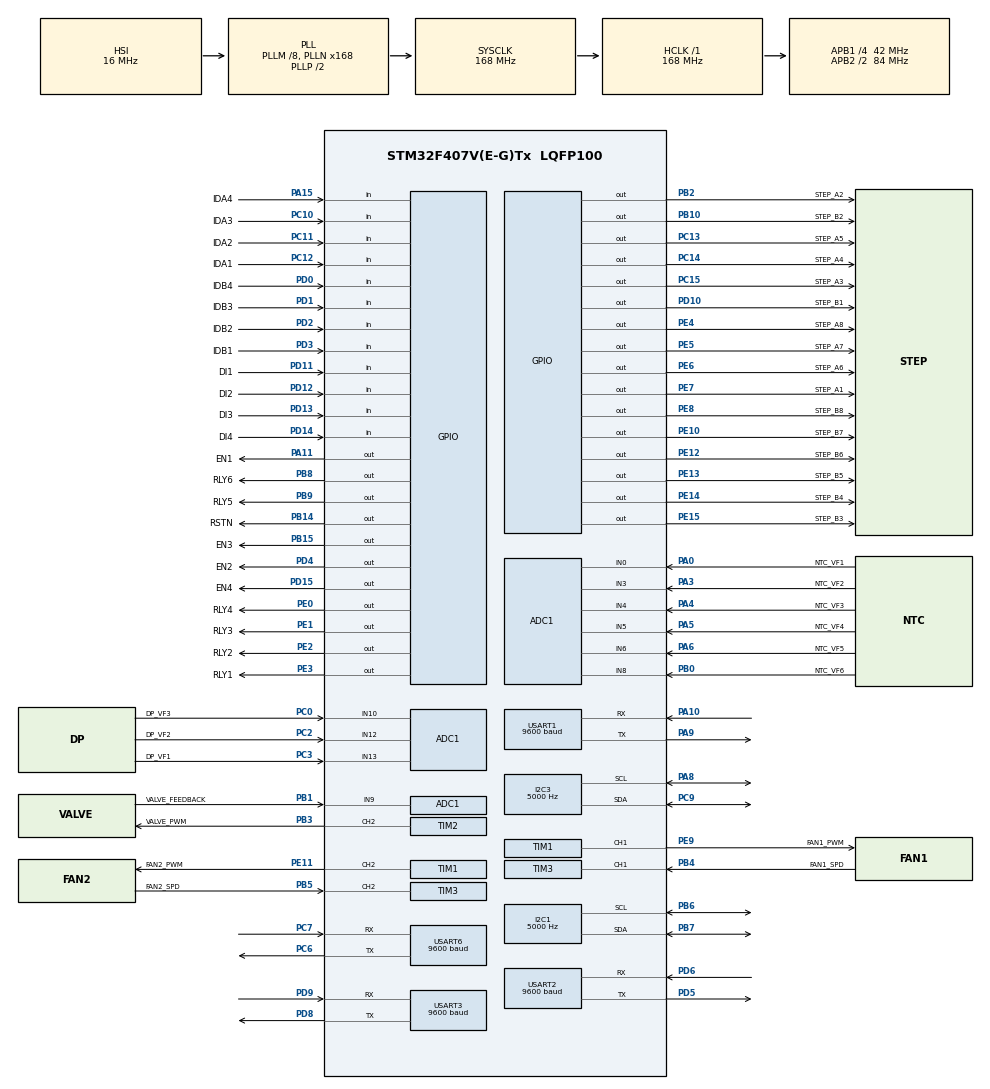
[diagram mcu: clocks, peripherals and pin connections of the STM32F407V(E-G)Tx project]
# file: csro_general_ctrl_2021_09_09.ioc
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ADC1.Channel-0\#ChannelRegularConversion=ADC_CHANNEL_13
ADC1.Channel-1\#ChannelRegularConversion=ADC_CHANNEL_12
ADC1.Channel-10\#ChannelRegularConversion=ADC_CHANNEL_TEMPSENSOR
ADC1.Channel-11\#ChannelRegularConversion=ADC_CHANNEL_VREFINT
ADC1.Channel-12\#ChannelRegularConversion=ADC_CHANNEL_VBAT
ADC1.Channel-2\#ChannelRegularConversion=ADC_CHANNEL_10
ADC1.Channel-3\#ChannelRegularConversion=ADC_CHANNEL_9
ADC1.Channel-4\#ChannelRegularConversion=ADC_CHANNEL_0
ADC1.Channel-5\#ChannelRegularConversion=ADC_CHANNEL_3
ADC1.Channel-6\#ChannelRegularConversion=ADC_CHANNEL_4
ADC1.Channel-7\#ChannelRegularConversion=ADC_CHANNEL_5
ADC1.Channel-8\#ChannelRegularConversion=ADC_CHANNEL_6
ADC1.Channel-9\#ChannelRegularConversion=ADC_CHANNEL_8
ADC1.ContinuousConvMode=ENABLE
ADC1.DMAContinuousRequests=ENABLE
ADC1.NbrOfConversion=13
ADC1.NbrOfConversionFlag=1
ADC1.Rank-0\#ChannelRegularConversion=1
ADC1.Rank-1\#ChannelRegularConversion=2
ADC1.Rank-10\#ChannelRegularConversion=11
ADC1.Rank-11\#ChannelRegularConversion=12
ADC1.Rank-12\#ChannelRegularConversion=13
ADC1.Rank-2\#ChannelRegularConversion=3
ADC1.Rank-3\#ChannelRegularConversion=4
ADC1.Rank-4\#ChannelRegularConversion=5
ADC1.Rank-5\#ChannelRegularConversion=6
ADC1.Rank-6\#ChannelRegularConversion=7
ADC1.Rank-7\#ChannelRegularConversion=8
ADC1.Rank-8\#ChannelRegularConversion=9
ADC1.Rank-9\#ChannelRegularConversion=10
ADC1.SamplingTime-0\#ChannelRegularConversion=ADC_SAMPLETIME_144CYCLES
ADC1.SamplingTime-1\#ChannelRegularConversion=ADC_SAMPLETIME_144CYCLES
ADC1.SamplingTime-10\#ChannelRegularConversion=ADC_SAMPLETIME_144CYCLES
ADC1.SamplingTime-11\#ChannelRegularConversion=ADC_SAMPLETIME_144CYCLES
ADC1.SamplingTime-12\#ChannelRegularConversion=ADC_SAMPLETIME_144CYCLES
ADC1.SamplingTime-2\#ChannelRegularConversion=ADC_SAMPLETIME_144CYCLES
ADC1.SamplingTime-3\#ChannelRegularConversion=ADC_SAMPLETIME_144CYCLES
ADC1.SamplingTime-4\#ChannelRegularConversion=ADC_SAMPLETIME_144CYCLES
ADC1.SamplingTime-5\#ChannelRegularConversion=ADC_SAMPLETIME_144CYCLES
ADC1.SamplingTime-6\#ChannelRegularConversion=ADC_SAMPLETIME_144CYCLES
ADC1.SamplingTime-7\#ChannelRegularConversion=ADC_SAMPLETIME_144CYCLES
ADC1.SamplingTime-8\#ChannelRegularConversion=ADC_SAMPLETIME_144CYCLES
ADC1.SamplingTime-9\#ChannelRegularConversion=ADC_SAMPLETIME_144CYCLES
ADC1.ScanConvMode=ENABLE
ADC1.master=1
Dma.ADC1.0.Direction=DMA_PERIPH_TO_MEMORY
Dma.ADC1.0.FIFOMode=DMA_FIFOMODE_DISABLE
Dma.ADC1.0.Instance=DMA2_Stream0
Dma.ADC1.0.MemDataAlignment=DMA_MDATAALIGN_WORD
Dma.ADC1.0.MemInc=DMA_MINC_ENABLE
Dma.ADC1.0.Mode=DMA_CIRCULAR
Dma.ADC1.0.PeriphDataAlignment=DMA_PDATAALIGN_WORD
Dma.ADC1.0.PeriphInc=DMA_PINC_DISABLE
Dma.ADC1.0.Priority=DMA_PRIORITY_LOW
Dma.Request0=ADC1
Dma.Request1=USART1_RX
Dma.Request2=USART1_TX
Dma.Request3=USART2_RX
Dma.Request4=USART2_TX
Dma.Request5=USART3_RX
Dma.Request6=USART3_TX
Dma.Request7=USART6_RX
Dma.Request8=USART6_TX
Dma.USART1_RX.1.Direction=DMA_PERIPH_TO_MEMORY
Dma.USART1_RX.1.FIFOMode=DMA_FIFOMODE_DISABLE
Dma.USART1_RX.1.Instance=DMA2_Stream2
Dma.USART1_RX.1.MemDataAlignment=DMA_MDATAALIGN_BYTE
Dma.USART1_RX.1.MemInc=DMA_MINC_ENABLE
Dma.USART1_RX.1.Mode=DMA_CIRCULAR
Dma.USART1_RX.1.PeriphDataAlignment=DMA_PDATAALIGN_BYTE
Dma.USART1_RX.1.PeriphInc=DMA_PINC_DISABLE
Dma.USART1_RX.1.Priority=DMA_PRIORITY_LOW
Dma.USART1_TX.2.Direction=DMA_MEMORY_TO_PERIPH
Dma.USART1_TX.2.FIFOMode=DMA_FIFOMODE_DISABLE
Dma.USART1_TX.2.Instance=DMA2_Stream7
Dma.USART1_TX.2.MemDataAlignment=DMA_MDATAALIGN_BYTE
Dma.USART1_TX.2.MemInc=DMA_MINC_ENABLE
Dma.USART1_TX.2.Mode=DMA_NORMAL
Dma.USART1_TX.2.PeriphDataAlignment=DMA_PDATAALIGN_BYTE
Dma.USART1_TX.2.PeriphInc=DMA_PINC_DISABLE
Dma.USART1_TX.2.Priority=DMA_PRIORITY_LOW
Dma.USART2_RX.3.Direction=DMA_PERIPH_TO_MEMORY
Dma.USART2_RX.3.FIFOMode=DMA_FIFOMODE_DISABLE
Dma.USART2_RX.3.Instance=DMA1_Stream5
Dma.USART2_RX.3.MemDataAlignment=DMA_MDATAALIGN_BYTE
Dma.USART2_RX.3.MemInc=DMA_MINC_ENABLE
Dma.USART2_RX.3.Mode=DMA_CIRCULAR
Dma.USART2_RX.3.PeriphDataAlignment=DMA_PDATAALIGN_BYTE
Dma.USART2_RX.3.PeriphInc=DMA_PINC_DISABLE
Dma.USART2_RX.3.Priority=DMA_PRIORITY_LOW
Dma.USART2_TX.4.Direction=DMA_MEMORY_TO_PERIPH
Dma.USART2_TX.4.FIFOMode=DMA_FIFOMODE_DISABLE
Dma.USART2_TX.4.Instance=DMA1_Stream6
Dma.USART2_TX.4.MemDataAlignment=DMA_MDATAALIGN_BYTE
Dma.USART2_TX.4.MemInc=DMA_MINC_ENABLE
Dma.USART2_TX.4.Mode=DMA_NORMAL
Dma.USART2_TX.4.PeriphDataAlignment=DMA_PDATAALIGN_BYTE
Dma.USART2_TX.4.PeriphInc=DMA_PINC_DISABLE
Dma.USART2_TX.4.Priority=DMA_PRIORITY_LOW
Dma.USART3_RX.5.Direction=DMA_PERIPH_TO_MEMORY
Dma.USART3_RX.5.FIFOMode=DMA_FIFOMODE_DISABLE
Dma.USART3_RX.5.Instance=DMA1_Stream1
Dma.USART3_RX.5.MemDataAlignment=DMA_MDATAALIGN_BYTE
Dma.USART3_RX.5.MemInc=DMA_MINC_ENABLE
Dma.USART3_RX.5.Mode=DMA_CIRCULAR
Dma.USART3_RX.5.PeriphDataAlignment=DMA_PDATAALIGN_BYTE
Dma.USART3_RX.5.PeriphInc=DMA_PINC_DISABLE
Dma.USART3_RX.5.Priority=DMA_PRIORITY_LOW
Dma.USART3_TX.6.Direction=DMA_MEMORY_TO_PERIPH
Dma.USART3_TX.6.FIFOMode=DMA_FIFOMODE_DISABLE
Dma.USART3_TX.6.Instance=DMA1_Stream3
Dma.USART3_TX.6.MemDataAlignment=DMA_MDATAALIGN_BYTE
Dma.USART3_TX.6.MemInc=DMA_MINC_ENABLE
Dma.USART3_TX.6.Mode=DMA_NORMAL
Dma.USART3_TX.6.PeriphDataAlignment=DMA_PDATAALIGN_BYTE
Dma.USART3_TX.6.PeriphInc=DMA_PINC_DISABLE
Dma.USART3_TX.6.Priority=DMA_PRIORITY_LOW
Dma.USART6_RX.7.Direction=DMA_PERIPH_TO_MEMORY
Dma.USART6_RX.7.FIFOMode=DMA_FIFOMODE_DISABLE
Dma.USART6_RX.7.Instance=DMA2_Stream1
Dma.USART6_RX.7.MemDataAlignment=DMA_MDATAALIGN_BYTE
Dma.USART6_RX.7.MemInc=DMA_MINC_ENABLE
Dma.USART6_RX.7.Mode=DMA_CIRCULAR
Dma.USART6_RX.7.PeriphDataAlignment=DMA_PDATAALIGN_BYTE
Dma.USART6_RX.7.PeriphInc=DMA_PINC_DISABLE
Dma.USART6_RX.7.Priority=DMA_PRIORITY_LOW
Dma.USART6_TX.8.Direction=DMA_MEMORY_TO_PERIPH
Dma.USART6_TX.8.FIFOMode=DMA_FIFOMODE_DISABLE
Dma.USART6_TX.8.Instance=DMA2_Stream6
Dma.USART6_TX.8.MemDataAlignment=DMA_MDATAALIGN_BYTE
Dma.USART6_TX.8.MemInc=DMA_MINC_ENABLE
Dma.USART6_TX.8.Mode=DMA_NORMAL
Dma.USART6_TX.8.PeriphDataAlignment=DMA_PDATAALIGN_BYTE
Dma.USART6_TX.8.PeriphInc=DMA_PINC_DISABLE
Dma.USART6_TX.8.Priority=DMA_PRIORITY_LOW
FREERTOS.Queues01=Queue01,16,uint16_t,0,Dynamic,NULL,NULL;Queue02,16,uint16_t,0,Dynamic,NULL,NULL
FREERTOS.Tasks01=Task01,55,128,StartTask01,Default,NULL,Dynamic,NULL,NULL;Task02,53,128,StartTask02,Default,NULL,Dynamic,NULL,NULL;Task03,51,128,StartTask03,Default,NULL,Dynamic,NULL,NULL;Task04,49,128,StartTask04,Default,NULL,Dynamic,NULL,NULL;Task05,47,128,StartTask05,Default,NULL,Dynamic,NULL,NULL;Task06,45,128,StartTask06,Default,NULL,Dynamic,NULL,NULL;Task07,43,128,StartTask07,Default,NULL,Dynamic,NULL,NULL;Task08,41,128,StartTask08,Default,NULL,Dynamic,NULL,NULL
FREERTOS.configUSE_NEWLIB_REENTRANT=1
I2C1.ClockSpeed=5000
I2C3.ClockSpeed=5000
Mcu.Family=STM32F4
Mcu.Name=STM32F407V(E-G)Tx
Mcu.Package=LQFP100
NVIC.ADC_IRQn=true\:5\:0\:false\:false\:true\:true\:true\:true
NVIC.DMA1_Stream1_IRQn=true\:5\:0\:false\:false\:true\:true\:false\:true
NVIC.DMA1_Stream3_IRQn=true\:5\:0\:false\:false\:true\:true\:false\:true
NVIC.DMA1_Stream5_IRQn=true\:5\:0\:false\:false\:true\:true\:false\:true
NVIC.DMA1_Stream6_IRQn=true\:5\:0\:false\:false\:true\:true\:false\:true
NVIC.DMA2_Stream0_IRQn=true\:5\:0\:false\:false\:true\:false\:false\:true
NVIC.DMA2_Stream1_IRQn=true\:5\:0\:false\:false\:true\:true\:false\:true
NVIC.DMA2_Stream2_IRQn=true\:5\:0\:false\:false\:true\:true\:false\:true
NVIC.DMA2_Stream6_IRQn=true\:5\:0\:false\:false\:true\:true\:false\:true
NVIC.DMA2_Stream7_IRQn=true\:5\:0\:false\:false\:true\:true\:false\:true
NVIC.PriorityGroup=NVIC_PRIORITYGROUP_4
NVIC.TIM3_IRQn=true\:5\:0\:false\:false\:true\:true\:true\:true
NVIC.TIM8_TRG_COM_TIM14_IRQn=true\:15\:0\:false\:false\:true\:false\:false\:true
NVIC.TimeBase=TIM8_TRG_COM_TIM14_IRQn
NVIC.TimeBaseIP=TIM14
NVIC.USART1_IRQn=true\:5\:0\:false\:false\:true\:true\:true\:true
NVIC.USART2_IRQn=true\:5\:0\:false\:false\:true\:true\:true\:true
NVIC.USART3_IRQn=true\:5\:0\:false\:false\:true\:true\:true\:true
NVIC.USART6_IRQn=true\:5\:0\:false\:false\:true\:true\:true\:true
PA0-WKUP.GPIO_Label=NTC_VF1
PA0-WKUP.Signal=ADCx_IN0
PA10.Mode=Asynchronous
PA10.Signal=USART1_RX
PA11.GPIO_Label=EN1
PA11.Signal=GPIO_Output
PA13.Mode=Serial_Wire
PA13.Signal=SYS_JTMS-SWDIO
PA14.Mode=Serial_Wire
PA14.Signal=SYS_JTCK-SWCLK
PA15.GPIO_Label=IDA4
PA15.Signal=GPIO_Input
PA3.GPIO_Label=NTC_VF2
PA3.Signal=ADCx_IN3
PA4.GPIO_Label=NTC_VF3
PA4.Signal=ADCx_IN4
PA5.GPIO_Label=NTC_VF4
PA5.Signal=ADCx_IN5
PA6.GPIO_Label=NTC_VF5
PA6.Signal=ADCx_IN6
PA8.Mode=I2C
PA8.Signal=I2C3_SCL
PA9.Mode=Asynchronous
PA9.Signal=USART1_TX
PB0.GPIO_Label=NTC_VF6
PB0.Signal=ADCx_IN8
PB1.GPIO_Label=VALVE_FEEDBACK
PB1.Signal=ADCx_IN9
PB10.GPIO_Label=STEP_B2
PB10.Signal=GPIO_Output
PB14.GPIO_Label=RSTN
PB14.Signal=GPIO_Output
PB15.GPIO_Label=EN3
PB15.Signal=GPIO_Output
PB2.GPIO_Label=STEP_A2
PB2.Signal=GPIO_Output
PB3.GPIO_Label=VALVE_PWM
PB3.Signal=S_TIM2_CH2
PB4.GPIO_Label=FAN1_SPD
PB4.Signal=S_TIM3_CH1
PB5.GPIO_Label=FAN2_SPD
PB5.Signal=S_TIM3_CH2
PB6.Mode=I2C
PB6.Signal=I2C1_SCL
PB7.Mode=I2C
PB7.Signal=I2C1_SDA
PB8.GPIO_Label=RLY6
PB8.Signal=GPIO_Output
PB9.GPIO_Label=RLY5
PB9.Signal=GPIO_Output
PC0.GPIO_Label=DP_VF3
PC0.Signal=ADCx_IN10
PC10.GPIO_Label=IDA3
PC10.Signal=GPIO_Input
PC11.GPIO_Label=IDA2
PC11.Signal=GPIO_Input
PC12.GPIO_Label=IDA1
PC12.Signal=GPIO_Input
PC13-ANTI_TAMP.GPIO_Label=STEP_A5
PC13-ANTI_TAMP.Signal=GPIO_Output
PC14-OSC32_IN.GPIO_Label=STEP_A4
PC14-OSC32_IN.Signal=GPIO_Output
PC15-OSC32_OUT.GPIO_Label=STEP_A3
PC15-OSC32_OUT.Signal=GPIO_Output
PC2.GPIO_Label=DP_VF2
PC2.Signal=ADCx_IN12
PC3.GPIO_Label=DP_VF1
PC3.Signal=ADCx_IN13
PC6.Mode=Asynchronous
PC6.Signal=USART6_TX
PC7.Mode=Asynchronous
PC7.Signal=USART6_RX
PC9.Mode=I2C
PC9.Signal=I2C3_SDA
PD0.GPIO_Label=IDB4
PD0.Signal=GPIO_Input
PD1.GPIO_Label=IDB3
PD1.Signal=GPIO_Input
PD10.GPIO_Label=STEP_B1
PD10.Signal=GPIO_Output
PD11.GPIO_Label=DI1
PD11.Signal=GPIO_Input
PD12.GPIO_Label=DI2
PD12.Signal=GPIO_Input
PD13.GPIO_Label=DI3
PD13.Signal=GPIO_Input
PD14.GPIO_Label=DI4
PD14.Signal=GPIO_Input
PD15.GPIO_Label=EN4
PD15.Signal=GPIO_Output
PD2.GPIO_Label=IDB2
PD2.Signal=GPIO_Input
PD3.GPIO_Label=IDB1
PD3.Signal=GPIO_Input
PD4.GPIO_Label=EN2
PD4.Signal=GPIO_Output
PD5.Mode=Asynchronous
PD5.Signal=USART2_TX
PD6.Mode=Asynchronous
PD6.Signal=USART2_RX
PD8.Mode=Asynchronous
PD8.Signal=USART3_TX
PD9.Mode=Asynchronous
PD9.Signal=USART3_RX
PE0.GPIO_Label=RLY4
PE0.Signal=GPIO_Output
PE1.GPIO_Label=RLY3
PE1.Signal=GPIO_Output
PE10.GPIO_Label=STEP_B7
PE10.Signal=GPIO_Output
PE11.GPIO_Label=FAN2_PWM
PE11.Signal=S_TIM1_CH2
PE12.GPIO_Label=STEP_B6
PE12.Signal=GPIO_Output
PE13.GPIO_Label=STEP_B5
PE13.Signal=GPIO_Output
PE14.GPIO_Label=STEP_B4
PE14.Signal=GPIO_Output
PE15.GPIO_Label=STEP_B3
PE15.Signal=GPIO_Output
PE2.GPIO_Label=RLY2
PE2.Signal=GPIO_Output
PE3.GPIO_Label=RLY1
PE3.Signal=GPIO_Output
PE4.GPIO_Label=STEP_A8
PE4.Signal=GPIO_Output
PE5.GPIO_Label=STEP_A7
PE5.Signal=GPIO_Output
PE6.GPIO_Label=STEP_A6
PE6.Signal=GPIO_Output
PE7.GPIO_Label=STEP_A1
PE7.Signal=GPIO_Output
PE8.GPIO_Label=STEP_B8
PE8.Signal=GPIO_Output
PE9.GPIO_Label=FAN1_PWM
PE9.Signal=S_TIM1_CH1
ProjectManager.HeapSize=0x800
ProjectManager.StackSize=0x800
ProjectManager.TargetToolchain=STM32CubeIDE
RCC.48MHZClocksFreq_Value=84000000
RCC.AHBFreq_Value=168000000
RCC.APB1CLKDivider=RCC_HCLK_DIV4
RCC.APB1Freq_Value=42000000
RCC.APB1TimFreq_Value=84000000
RCC.APB2CLKDivider=RCC_HCLK_DIV2
RCC.APB2Freq_Value=84000000
RCC.APB2TimFreq_Value=168000000
RCC.CortexFreq_Value=168000000
RCC.HCLKFreq_Value=168000000
RCC.HSE_VALUE=25000000
RCC.HSI_VALUE=16000000
RCC.LSE_VALUE=32768
RCC.PLLM=8
RCC.PLLN=168
RCC.SYSCLKFreq_VALUE=168000000
RCC.SYSCLKSource=RCC_SYSCLKSOURCE_PLLCLK
RCC.VCOOutputFreq_Value=336000000
SH.ADCx_IN0.0=ADC1_IN0,IN0
SH.ADCx_IN10.0=ADC1_IN10,IN10
SH.ADCx_IN12.0=ADC1_IN12,IN12
SH.ADCx_IN13.0=ADC1_IN13,IN13
SH.ADCx_IN3.0=ADC1_IN3,IN3
SH.ADCx_IN4.0=ADC1_IN4,IN4
SH.ADCx_IN5.0=ADC1_IN5,IN5
SH.ADCx_IN6.0=ADC1_IN6,IN6
SH.ADCx_IN8.0=ADC1_IN8,IN8
SH.ADCx_IN9.0=ADC1_IN9,IN9
SH.S_TIM1_CH1.0=TIM1_CH1,PWM Generation1 CH1
SH.S_TIM1_CH2.0=TIM1_CH2,PWM Generation2 CH2
SH.S_TIM2_CH2.0=TIM2_CH2,PWM Generation2 CH2
SH.S_TIM3_CH1.0=TIM3_CH1,Input_Capture1_from_TI1
SH.S_TIM3_CH2.0=TIM3_CH2,Input_Capture2_from_TI2
TIM1.Channel-PWM\ Generation1\ CH1=TIM_CHANNEL_1
TIM1.Channel-PWM\ Generation2\ CH2=TIM_CHANNEL_2
TIM1.Period=1000
TIM1.Prescaler=167
TIM1.Pulse-PWM\ Generation1\ CH1=300
TIM1.Pulse-PWM\ Generation2\ CH2=600
TIM2.Channel-PWM\ Generation2\ CH2=TIM_CHANNEL_2
TIM2.Period=1000
TIM2.Prescaler=167
TIM2.Pulse-PWM\ Generation2\ CH2=500
TIM3.Channel-Input_Capture1_from_TI1=TIM_CHANNEL_1
TIM3.Channel-Input_Capture2_from_TI2=TIM_CHANNEL_2
USART1.BaudRate=9600
USART1.VirtualMode=VM_ASYNC
USART2.BaudRate=9600
USART2.VirtualMode=VM_ASYNC
USART3.BaudRate=9600
USART3.VirtualMode=VM_ASYNC
USART6.BaudRate=9600
USART6.VirtualMode=VM_ASYNC
VP_ADC1_TempSens_Input.Mode=IN-TempSens
VP_ADC1_Vbat_Input.Mode=IN-Vbat
VP_ADC1_Vref_Input.Mode=IN-Vrefint
VP_FREERTOS_VS_CMSIS_V2.Mode=CMSIS_V2
VP_SYS_VS_tim14.Mode=TIM14
VP_TIM1_VS_ClockSourceINT.Mode=Internal
VP_TIM2_VS_ClockSourceINT.Mode=Internal
VP_TIM3_VS_ClockSourceINT.Mode=Internal
board=custom

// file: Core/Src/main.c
/* USER CODE BEGIN Header */
/**
  ******************************************************************************
  * @file           : main.c
  * @brief          : Main program body
  ******************************************************************************
  * @attention
  *
  * <h2><center>&copy; Copyright (c) 2021 STMicroelectronics.
  * All rights reserved.</center></h2>
  *
  * This software component is licensed by ST under BSD 3-Clause license,
  * the "License"; You may not use this file except in compliance with the
  * License. You may obtain a copy of the License at:
  *                        opensource.org/licenses/BSD-3-Clause
  *
  ******************************************************************************
  */
/* USER CODE END Header */
#include "main.h"
#include "cmsis_os.h"
#include "adc.h"
#include "dma.h"
#include "i2c.h"
#include "tim.h"
#include "usart.h"
#include "gpio.h"

void SystemClock_Config(void);
void MX_FREERTOS_Init(void);

int main(void)
{

  /* MCU Configuration--------------------------------------------------------*/

  /* Reset of all peripherals, Initializes the Flash interface and the Systick. */
  HAL_Init();

  /* Configure the system clock */
  SystemClock_Config();

  /* Initialize all configured peripherals */
  MX_GPIO_Init();
  MX_DMA_Init();
  MX_ADC1_Init();
  MX_I2C1_Init();
  MX_I2C3_Init();
  MX_TIM1_Init();
  MX_TIM2_Init();
  MX_TIM3_Init();
  MX_USART1_UART_Init();
  MX_USART2_UART_Init();
  MX_USART3_UART_Init();
  MX_USART6_UART_Init();

  /* Init scheduler */
  osKernelInitialize();  /* Call init function for freertos objects (in freertos.c) */
  MX_FREERTOS_Init();
  /* Start scheduler */
  osKernelStart();

  /* We should never get here as control is now taken by the scheduler */
  /* Infinite loop */
  while (1)
  {

  }
}

void SystemClock_Config(void)
{
  RCC_OscInitTypeDef RCC_OscInitStruct = {0};
  RCC_ClkInitTypeDef RCC_ClkInitStruct = {0};

  /** Configure the main internal regulator output voltage
  */
  __HAL_RCC_PWR_CLK_ENABLE();
  __HAL_PWR_VOLTAGESCALING_CONFIG(PWR_REGULATOR_VOLTAGE_SCALE1);
  /** Initializes the RCC Oscillators according to the specified parameters
  * in the RCC_OscInitTypeDef structure.
  */
  RCC_OscInitStruct.OscillatorType = RCC_OSCILLATORTYPE_HSI;
  RCC_OscInitStruct.HSIState = RCC_HSI_ON;
  RCC_OscInitStruct.HSICalibrationValue = RCC_HSICALIBRATION_DEFAULT;
  RCC_OscInitStruct.PLL.PLLState = RCC_PLL_ON;
  RCC_OscInitStruct.PLL.PLLSource = RCC_PLLSOURCE_HSI;
  RCC_OscInitStruct.PLL.PLLM = 8;
  RCC_OscInitStruct.PLL.PLLN = 168;
  RCC_OscInitStruct.PLL.PLLP = RCC_PLLP_DIV2;
  RCC_OscInitStruct.PLL.PLLQ = 4;
  if (HAL_RCC_OscConfig(&RCC_OscInitStruct) != HAL_OK)
  {
    Error_Handler();
  }
  /** Initializes the CPU, AHB and APB buses clocks
  */
  RCC_ClkInitStruct.ClockType = RCC_CLOCKTYPE_HCLK|RCC_CLOCKTYPE_SYSCLK
                              |RCC_CLOCKTYPE_PCLK1|RCC_CLOCKTYPE_PCLK2;
  RCC_ClkInitStruct.SYSCLKSource = RCC_SYSCLKSOURCE_PLLCLK;
  RCC_ClkInitStruct.AHBCLKDivider = RCC_SYSCLK_DIV1;
  RCC_ClkInitStruct.APB1CLKDivider = RCC_HCLK_DIV4;
  RCC_ClkInitStruct.APB2CLKDivider = RCC_HCLK_DIV2;

  if (HAL_RCC_ClockConfig(&RCC_ClkInitStruct, FLASH_LATENCY_5) != HAL_OK)
  {
    Error_Handler();
  }
}

void HAL_TIM_PeriodElapsedCallback(TIM_HandleTypeDef *htim)
{
  if (htim->Instance == TIM14) {
    HAL_IncTick();
  }
}

void Error_Handler(void)
{
  __disable_irq();
  while (1)
  {
  }
}

/************************ (C) COPYRIGHT STMicroelectronics *****END OF FILE****/

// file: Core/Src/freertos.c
/* USER CODE BEGIN Header */
/**
  ******************************************************************************
  * File Name          : freertos.c
  * Description        : Code for freertos applications
  ******************************************************************************
  * @attention
  *
  * <h2><center>&copy; Copyright (c) 2021 STMicroelectronics.
  * All rights reserved.</center></h2>
  *
  * This software component is licensed by ST under Ultimate Liberty license
  * SLA0044, the "License"; You may not use this file except in compliance with
  * the License. You may obtain a copy of the License at:
  *                             www.st.com/SLA0044
  *
  ******************************************************************************
  */
/* USER CODE END Header */

#include "FreeRTOS.h"
#include "task.h"
#include "main.h"
#include "cmsis_os.h"

/* USER CODE BEGIN Includes */
#include "fnd_input.h"
#include "fnd_output.h"
#include "fnd_com.h"

/* USER CODE END Includes */

/* Definitions for Task01 */
osThreadId_t Task01Handle;
const osThreadAttr_t Task01_attributes = {
    .name = "Task01",
    .stack_size = 128 * 4,
    .priority = (osPriority_t)osPriorityRealtime7,
};
/* Definitions for Task02 */
osThreadId_t Task02Handle;
const osThreadAttr_t Task02_attributes = {
    .name = "Task02",
    .stack_size = 128 * 4,
    .priority = (osPriority_t)osPriorityRealtime5,
};
/* Definitions for Task03 */
osThreadId_t Task03Handle;
const osThreadAttr_t Task03_attributes = {
    .name = "Task03",
    .stack_size = 128 * 4,
    .priority = (osPriority_t)osPriorityRealtime3,
};
/* Definitions for Task04 */
osThreadId_t Task04Handle;
const osThreadAttr_t Task04_attributes = {
    .name = "Task04",
    .stack_size = 128 * 4,
    .priority = (osPriority_t)osPriorityRealtime1,
};
/* Definitions for Task05 */
osThreadId_t Task05Handle;
const osThreadAttr_t Task05_attributes = {
    .name = "Task05",
    .stack_size = 128 * 4,
    .priority = (osPriority_t)osPriorityHigh7,
};
/* Definitions for Task06 */
osThreadId_t Task06Handle;
const osThreadAttr_t Task06_attributes = {
    .name = "Task06",
    .stack_size = 128 * 4,
    .priority = (osPriority_t)osPriorityHigh5,
};
/* Definitions for Task07 */
osThreadId_t Task07Handle;
const osThreadAttr_t Task07_attributes = {
    .name = "Task07",
    .stack_size = 128 * 4,
    .priority = (osPriority_t)osPriorityHigh3,
};
/* Definitions for Task08 */
osThreadId_t Task08Handle;
const osThreadAttr_t Task08_attributes = {
    .name = "Task08",
    .stack_size = 128 * 4,
    .priority = (osPriority_t)osPriorityHigh1,
};
/* Definitions for Queue01 */
osMessageQueueId_t Queue01Handle;
const osMessageQueueAttr_t Queue01_attributes = {
    .name = "Queue01"};
/* Definitions for Queue02 */
osMessageQueueId_t Queue02Handle;
const osMessageQueueAttr_t Queue02_attributes = {
    .name = "Queue02"};

void StartTask01(void *argument);
void StartTask02(void *argument);
void StartTask03(void *argument);
void StartTask04(void *argument);
void StartTask05(void *argument);
void StartTask06(void *argument);
void StartTask07(void *argument);
void StartTask08(void *argument);

void MX_FREERTOS_Init(void); /* (MISRA C 2004 rule 8.1) */

void MX_FREERTOS_Init(void)
{
  /* USER CODE BEGIN Init */
  fnd_com_modbus_rtu_init();

  /* USER CODE END Init */

  /* Create the queue(s) */
  /* creation of Queue01 */
  Queue01Handle = osMessageQueueNew(16, sizeof(uint16_t), &Queue01_attributes);

  /* creation of Queue02 */
  Queue02Handle = osMessageQueueNew(16, sizeof(uint16_t), &Queue02_attributes);

  /* Create the thread(s) */
  /* creation of Task01 */
  Task01Handle = osThreadNew(StartTask01, NULL, &Task01_attributes);

  /* creation of Task02 */
  Task02Handle = osThreadNew(StartTask02, NULL, &Task02_attributes);

  /* creation of Task03 */
  Task03Handle = osThreadNew(StartTask03, NULL, &Task03_attributes);

  /* creation of Task04 */
  Task04Handle = osThreadNew(StartTask04, NULL, &Task04_attributes);

  /* creation of Task05 */
  Task05Handle = osThreadNew(StartTask05, NULL, &Task05_attributes);

  /* creation of Task06 */
  Task06Handle = osThreadNew(StartTask06, NULL, &Task06_attributes);

  /* creation of Task07 */
  Task07Handle = osThreadNew(StartTask07, NULL, &Task07_attributes);

  /* creation of Task08 */
  Task08Handle = osThreadNew(StartTask08, NULL, &Task08_attributes);

}

void StartTask01(void *argument)
{
  /* USER CODE BEGIN StartTask01 */
  /* Infinite loop */
  for (;;)
  {
    fnd_com_modbus_rtu_slave1_wait();
  }
  /* USER CODE END StartTask01 */
}

void StartTask02(void *argument)
{
  /* USER CODE BEGIN StartTask02 */
  /* Infinite loop */
  for (;;)
  {
    fnd_com_modbus_rtu_slave2_wait();
  }
  /* USER CODE END StartTask02 */
}

void StartTask03(void *argument)
{
  /* USER CODE BEGIN StartTask03 */
  /* Infinite loop */
  for (;;)
  {
    fnd_com_modbus_rtu_master1_read_write();
    osDelay(1000);
  }
  /* USER CODE END StartTask03 */
}

void StartTask04(void *argument)
{
  /* USER CODE BEGIN StartTask04 */
  /* Infinite loop */
  for (;;)
  {
    fnd_com_modbus_rtu_master2_read_write();
  }
  /* USER CODE END StartTask04 */
}

void StartTask05(void *argument)
{
  /* USER CODE BEGIN StartTask05 */
  fnd_output_stepper_init();
  /* Infinite loop */
  for (;;)
  {
    osDelay(10);
    fnd_output_stepper_10ms_tick();
  }
  /* USER CODE END StartTask05 */
}

void StartTask06(void *argument)
{
  /* USER CODE BEGIN StartTask06 */
  fnd_input_peripheral_init();
  fnd_output_peripheral_init();
  /* Infinite loop */
  for (;;)
  {
    osDelay(100);
    fnd_input_update_value();

    for (uint8_t i = 0; i < 13; i++)
    {
      sys_regs.inputs[200 + i] = sys_regs.holdings[200 + i];
    }
    fnd_output_update_value();
  }
  /* USER CODE END StartTask06 */
}

void StartTask07(void *argument)
{
  /* USER CODE BEGIN StartTask07 */
  /* Infinite loop */
  for (;;)
  {
    osDelay(1000);
    fnd_input_update_sht_value();
  }
  /* USER CODE END StartTask07 */
}

void StartTask08(void *argument)
{
  /* USER CODE BEGIN StartTask08 */

  /* Infinite loop */
  for (;;)
  {
    osDelay(1000);
  }
  /* USER CODE END StartTask08 */
}

/************************ (C) COPYRIGHT STMicroelectronics *****END OF FILE****/
